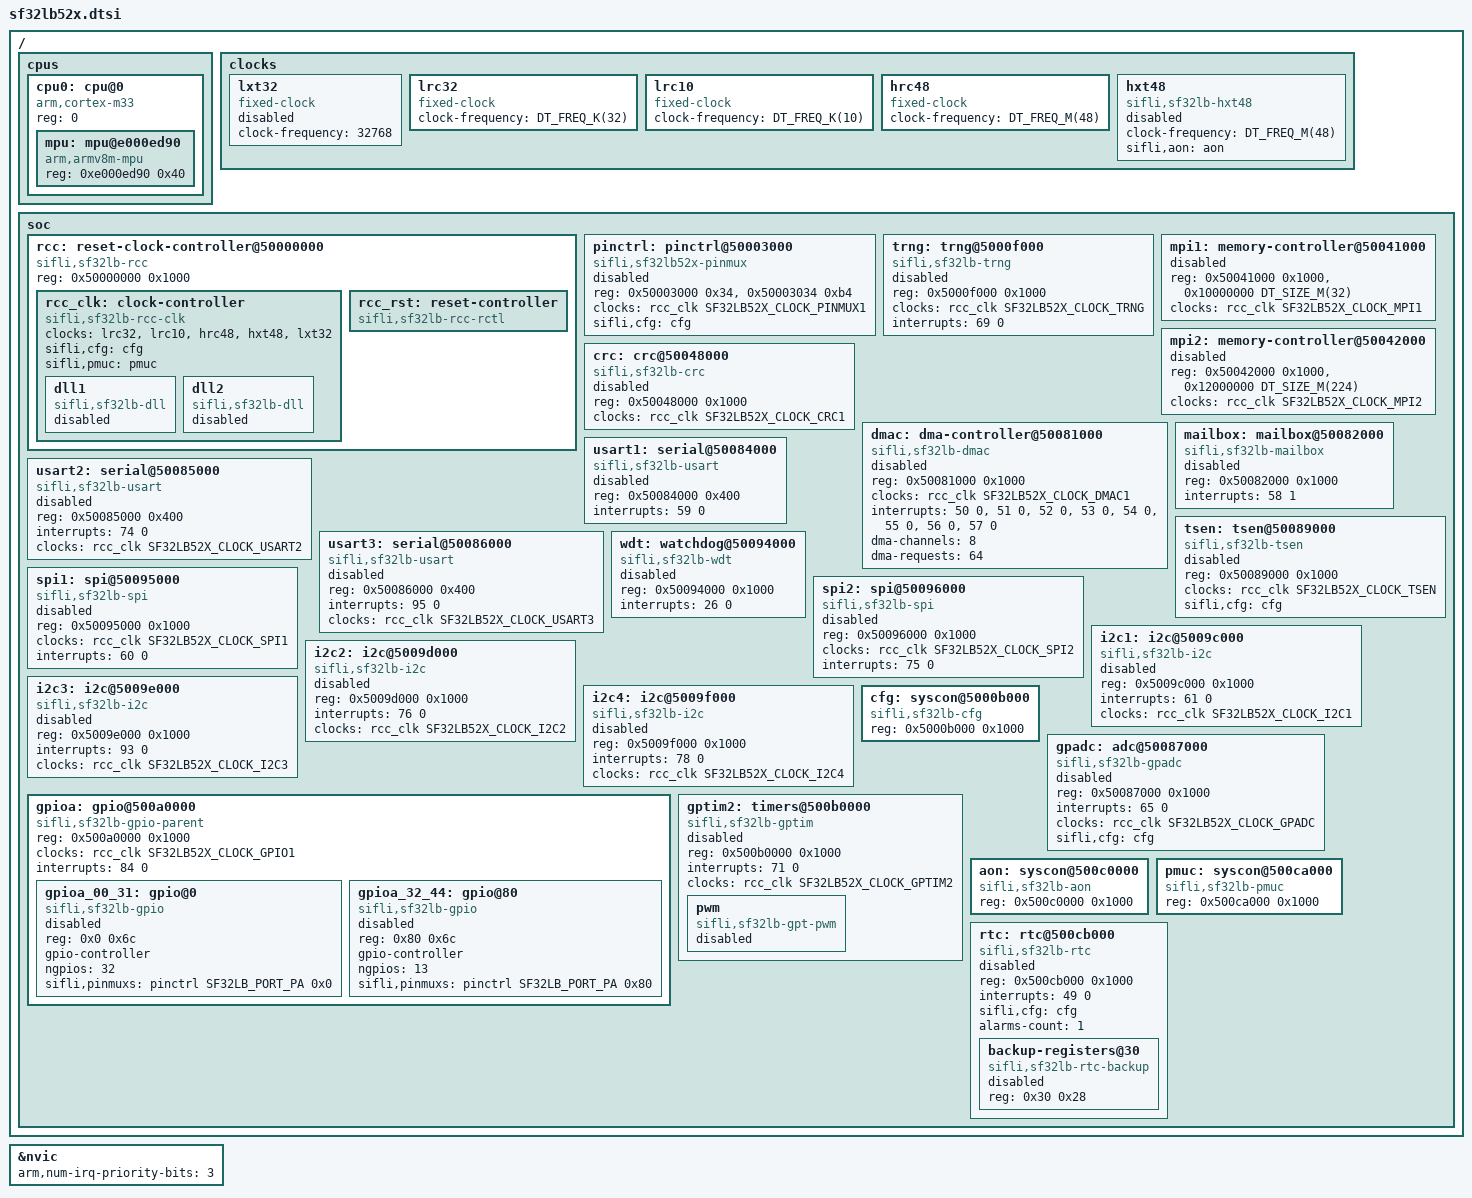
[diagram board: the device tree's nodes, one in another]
/*
 * Copyright (c) 2025 Core Devices LLC
 * Copyright (c) 2025 SiFli Technologies(Nanjing) Co., Ltd
 * SPDX-License-Identifier: Apache-2.0
 */

#include <arm/armv8-m.dtsi>
#include <freq.h>
#include <mem.h>

#include <zephyr/dt-bindings/clock/sf32lb52x-clocks.h>
#include <zephyr/dt-bindings/pinctrl/sf32lb52x-pinctrl.h>

/ {
	cpus {
		#address-cells = <1>;
		#size-cells = <0>;

		cpu0: cpu@0 {
			compatible = "arm,cortex-m33";
			reg = <0>;
			#address-cells = <1>;
			#size-cells = <1>;

			mpu: mpu@e000ed90 {
				compatible = "arm,armv8m-mpu";
				reg = <0xe000ed90 0x40>;
			};
		};
	};

	clocks {
		lxt32: lxt32 {
			compatible = "fixed-clock";
			clock-frequency = <32768>;
			#clock-cells = <0>;
			status = "disabled";
		};

		lrc32: lrc32 {
			compatible = "fixed-clock";
			clock-frequency = <DT_FREQ_K(32)>;
			#clock-cells = <0>;
		};

		lrc10: lrc10 {
			compatible = "fixed-clock";
			clock-frequency = <DT_FREQ_K(10)>;
			#clock-cells = <0>;
		};

		hrc48: hrc48 {
			compatible = "fixed-clock";
			clock-frequency = <DT_FREQ_M(48)>;
			#clock-cells = <0>;
		};

		hxt48: hxt48 {
			compatible = "sifli,sf32lb-hxt48";
			clock-frequency = <DT_FREQ_M(48)>;
			#clock-cells = <0>;
			sifli,aon = <&aon>;
			status = "disabled";
		};
	};

	soc {
		rcc: reset-clock-controller@50000000 {
			compatible = "sifli,sf32lb-rcc";
			reg = <0x50000000 0x1000>;

			rcc_clk: clock-controller {
				compatible = "sifli,sf32lb-rcc-clk";
				clocks = <&lrc32>, <&lrc10>, <&hrc48>, <&hxt48>,
					 <&lxt32>;
				clock-names = "lrc32", "lrc10", "hrc48",
					      "hxt48", "lxt32";
				#clock-cells = <1>;
				sifli,cfg = <&cfg>;
				sifli,pmuc = <&pmuc>;

				dll1: dll1 {
					compatible = "sifli,sf32lb-dll";
					status = "disabled";
				};

				dll2: dll2 {
					compatible = "sifli,sf32lb-dll";
					status = "disabled";
				};
			};

			rcc_rst: reset-controller {
				compatible = "sifli,sf32lb-rcc-rctl";
				#reset-cells = <1>;
			};
		};

		pinctrl: pinctrl@50003000 {
			compatible = "sifli,sf32lb52x-pinmux";
			reg = <0x50003000 0x34>, <0x50003034 0xb4>;
			reg-names = "pad_sa", "pad_pa";
			clocks = <&rcc_clk SF32LB52X_CLOCK_PINMUX1>;
			#sifli,pinmux-cells = <2>;
			sifli,cfg = <&cfg>;
			status = "disabled";
		};

		trng: trng@5000f000 {
			compatible = "sifli,sf32lb-trng";
			reg = <0x5000f000 0x1000>;
			clocks = <&rcc_clk SF32LB52X_CLOCK_TRNG>;
			interrupts = <69 0>;
			status = "disabled";
		};

		mpi1: memory-controller@50041000 {
			/*
			 * configure compatible depending on memory type, choices:
			 * - sifli,sf32lb-mpi-qspi-nor
			 */
			reg = <0x50041000 0x1000>, <0x10000000 DT_SIZE_M(32)>;
			reg-names = "ctrl", "nor";
			clocks = <&rcc_clk SF32LB52X_CLOCK_MPI1>;
			#address-cells = <1>;
			#size-cells = <0>;
			status = "disabled";
		};

		mpi2: memory-controller@50042000 {
			/*
			 * configure compatible depending on memory type, choices:
			 * - sifli,sf32lb-mpi-qspi-nor
			 */
			reg = <0x50042000 0x1000>, <0x12000000 DT_SIZE_M(224)>;
			reg-names = "ctrl", "nor";
			#address-cells = <1>;
			#size-cells = <0>;
			clocks = <&rcc_clk SF32LB52X_CLOCK_MPI2>;
			status = "disabled";
		};

		crc: crc@50048000 {
			compatible = "sifli,sf32lb-crc";
			reg = <0x50048000 0x1000>;
			clocks = <&rcc_clk SF32LB52X_CLOCK_CRC1>;
			status = "disabled";
		};

		dmac: dma-controller@50081000 {
			compatible = "sifli,sf32lb-dmac";
			reg = <0x50081000 0x1000>;
			clocks = <&rcc_clk SF32LB52X_CLOCK_DMAC1>;
			interrupts = <50 0>, <51 0>, <52 0>, <53 0>,
				     <54 0>, <55 0>, <56 0>, <57 0>;
			dma-channels = <8>;
			dma-requests = <64>;
			#dma-cells = <3>;
			status = "disabled";
		};

		mailbox: mailbox@50082000 {
			compatible = "sifli,sf32lb-mailbox";
			reg = <0x50082000 0x1000>;
			interrupts = <58 1>;
			status = "disabled";
		};

		usart1: serial@50084000 {
			compatible = "sifli,sf32lb-usart";
			reg = <0x50084000 0x400>;
			interrupts = <59 0>;
			status = "disabled";
		};

		usart2: serial@50085000 {
			compatible = "sifli,sf32lb-usart";
			reg = <0x50085000 0x400>;
			interrupts = <74 0>;
			clocks = <&rcc_clk SF32LB52X_CLOCK_USART2>;
			status = "disabled";
		};

		usart3: serial@50086000 {
			compatible = "sifli,sf32lb-usart";
			reg = <0x50086000 0x400>;
			interrupts = <95 0>;
			clocks = <&rcc_clk SF32LB52X_CLOCK_USART3>;
			status = "disabled";
		};

		tsen: tsen@50089000 {
			compatible = "sifli,sf32lb-tsen";
			reg = <0x50089000 0x1000>;
			clocks = <&rcc_clk SF32LB52X_CLOCK_TSEN>;
			sifli,cfg = <&cfg>;
			status = "disabled";
		};

		wdt: watchdog@50094000 {
			compatible = "sifli,sf32lb-wdt";
			reg = <0x50094000 0x1000>;
			interrupts = <26 0>;
			status = "disabled";
		};

		spi1: spi@50095000 {
			compatible = "sifli,sf32lb-spi";
			#address-cells = <1>;
			#size-cells = <0>;
			reg = <0x50095000 0x1000>;
			clocks = <&rcc_clk SF32LB52X_CLOCK_SPI1>;
			interrupts = <60 0>;
			status = "disabled";
		};

		spi2: spi@50096000 {
			compatible = "sifli,sf32lb-spi";
			#address-cells = <1>;
			#size-cells = <0>;
			reg = <0x50096000 0x1000>;
			clocks = <&rcc_clk SF32LB52X_CLOCK_SPI2>;
			interrupts = <75 0>;
			status = "disabled";
		};

		i2c1: i2c@5009c000 {
			compatible = "sifli,sf32lb-i2c";
			reg = <0x5009c000 0x1000>;
			interrupts = <61 0>;
			#address-cells = <1>;
			#size-cells = <0>;
			clocks = <&rcc_clk SF32LB52X_CLOCK_I2C1>;
			status = "disabled";
		};

		i2c2: i2c@5009d000 {
			compatible = "sifli,sf32lb-i2c";
			reg = <0x5009d000 0x1000>;
			interrupts = <76 0>;
			#address-cells = <1>;
			#size-cells = <0>;
			clocks = <&rcc_clk SF32LB52X_CLOCK_I2C2>;
			status = "disabled";
		};

		i2c3: i2c@5009e000 {
			compatible = "sifli,sf32lb-i2c";
			reg = <0x5009e000 0x1000>;
			interrupts = <93 0>;
			#address-cells = <1>;
			#size-cells = <0>;
			clocks = <&rcc_clk SF32LB52X_CLOCK_I2C3>;
			status = "disabled";
		};

		i2c4: i2c@5009f000 {
			compatible = "sifli,sf32lb-i2c";
			reg = <0x5009f000 0x1000>;
			interrupts = <78 0>;
			#address-cells = <1>;
			#size-cells = <0>;
			clocks = <&rcc_clk SF32LB52X_CLOCK_I2C4>;
			status = "disabled";
		};

		gpioa: gpio@500a0000 {
			compatible = "sifli,sf32lb-gpio-parent";
			reg = <0x500a0000 0x1000>;
			ranges = <0x0 0x500a0000 0x1000>;
			#address-cells = <1>;
			#size-cells = <1>;
			clocks = <&rcc_clk SF32LB52X_CLOCK_GPIO1>;
			interrupts = <84 0>;

			/*
			 * Split into 32 pin blocks due to Zephyr requiring GPIO
			 * ports to have a maximum of 32 pins. This is a
			 * Zephyrism, but it is what it is!
			 */
			gpioa_00_31: gpio@0 {
				compatible = "sifli,sf32lb-gpio";
				reg = <0x0 0x6c>;
				#gpio-cells = <2>;
				gpio-controller;
				ngpios = <32>;
				sifli,pinmuxs = <&pinctrl SF32LB_PORT_PA 0x0>;
				status = "disabled";
			};

			gpioa_32_44: gpio@80 {
				compatible = "sifli,sf32lb-gpio";
				reg = <0x80 0x6c>;
				#gpio-cells = <2>;
				gpio-controller;
				ngpios = <13>;
				sifli,pinmuxs = <&pinctrl SF32LB_PORT_PA 0x80>;
				status = "disabled";
			};
		};

		cfg: syscon@5000b000 {
			compatible = "sifli,sf32lb-cfg", "syscon";
			reg = <0x5000b000 0x1000>;
		};

		gpadc: adc@50087000 {
			compatible = "sifli,sf32lb-gpadc";
			reg = <0x50087000 0x1000>;
			interrupts = <65 0>;
			clocks = <&rcc_clk SF32LB52X_CLOCK_GPADC>;
			sifli,cfg = <&cfg>;
			#io-channel-cells = <1>;
			status = "disabled";
		};

		gptim2: timers@500b0000 {
			compatible = "sifli,sf32lb-gptim";
			reg = <0x500b0000 0x1000>;
			interrupts = <71 0>;
			clocks = <&rcc_clk SF32LB52X_CLOCK_GPTIM2>;
			status = "disabled";

			pwm {
				compatible = "sifli,sf32lb-gpt-pwm";
				#pwm-cells = <3>;
				status = "disabled";
			};
		};

		aon: syscon@500c0000 {
			compatible = "sifli,sf32lb-aon", "syscon";
			reg = <0x500c0000 0x1000>;
		};

		pmuc: syscon@500ca000 {
			compatible = "sifli,sf32lb-pmuc", "syscon";
			reg = <0x500ca000 0x1000>;
		};

		rtc: rtc@500cb000 {
			compatible = "sifli,sf32lb-rtc";
			reg = <0x500cb000 0x1000>;
			ranges = <0x0 0x500cb000 0x1000>;
			#address-cells = <1>;
			#size-cells = <1>;
			interrupts = <49 0>;
			sifli,cfg = <&cfg>;
			alarms-count = <1>;
			status = "disabled";

			backup-registers@30 {
				compatible = "sifli,sf32lb-rtc-backup";
				reg = <0x30 0x28>;
				status = "disabled";
			};
		};
	};
};

&nvic {
	arm,num-irq-priority-bits = <3>;
};
